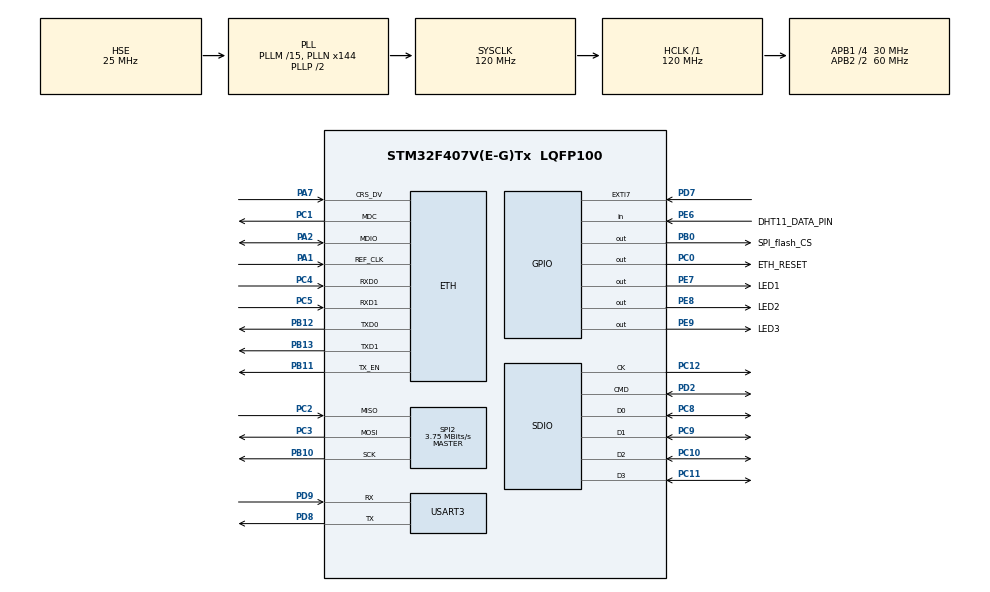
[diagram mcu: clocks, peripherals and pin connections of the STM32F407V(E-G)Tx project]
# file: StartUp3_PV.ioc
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Dma.Request0=USART3_TX
Dma.USART3_TX.0.Channel=DMA_CHANNEL_4
Dma.USART3_TX.0.Direction=DMA_MEMORY_TO_PERIPH
Dma.USART3_TX.0.FIFOMode=DMA_FIFOMODE_DISABLE
Dma.USART3_TX.0.Instance=DMA1_Stream3
Dma.USART3_TX.0.MemDataAlignment=DMA_MDATAALIGN_BYTE
Dma.USART3_TX.0.MemInc=DMA_MINC_ENABLE
Dma.USART3_TX.0.Mode=DMA_NORMAL
Dma.USART3_TX.0.PeriphDataAlignment=DMA_PDATAALIGN_BYTE
Dma.USART3_TX.0.PeriphInc=DMA_PINC_DISABLE
Dma.USART3_TX.0.Priority=DMA_PRIORITY_LOW
ETH.MACAddr=00\:80\:E1\:00\:00\:02
ETH.MediaInterface=ETH_MEDIA_INTERFACE_RMII
ETH.PHY_READ_TO=0x0004FFFF
ETH.PHY_WRITE_TO=0x0004FFFF
ETH.PhyAddress=0
FREERTOS.BinarySemaphores01=recFlag
FREERTOS.Tasks01=defaultTask,0,128,StartDefaultTask,Default
LWIP.LWIP_NETIF_LINK_CALLBACK=1
LWIP.LWIP_NETIF_LOOPBACK=0
LWIP.LWIP_NETIF_STATUS_CALLBACK=1
LWIP.LWIP_UDP=1
LWIP.MEMP_NUM_TCP_PCB=6
LWIP.MEMP_NUM_UDP_PCB=3
LWIP.TCP_TTL=63
Mcu.Family=STM32F4
Mcu.Name=STM32F407V(E-G)Tx
Mcu.Package=LQFP100
NVIC.DMA1_Stream3_IRQn=true\:5\:0\:false\:false\:true
NVIC.ETH_IRQn=true\:5\:0\:false\:false\:true
NVIC.EXTI9_5_IRQn=true\:13\:0\:true\:false\:true
NVIC.PriorityGroup=NVIC_PRIORITYGROUP_4
NVIC.SDIO_IRQn=true\:13\:0\:true\:false\:true
NVIC.SPI2_IRQn=true\:13\:0\:true\:false\:true
NVIC.TIM4_IRQn=true\:13\:0\:true\:false\:true
NVIC.TIM6_DAC_IRQn=true\:0\:0\:false\:false\:true
NVIC.TIM7_IRQn=true\:13\:0\:true\:false\:true
NVIC.TimeBase=TIM6_DAC_IRQn
NVIC.TimeBaseIP=TIM6
NVIC.USART3_IRQn=true\:13\:0\:true\:false\:true
PA1.Mode=RMII
PA1.Signal=ETH_REF_CLK
PA13.Mode=Serial-Wire
PA13.Signal=SYS_JTMS-SWDIO
PA14.Mode=Serial-Wire
PA14.Signal=SYS_JTCK-SWCLK
PA2.Mode=RMII
PA2.Signal=ETH_MDIO
PA7.Mode=RMII
PA7.Signal=ETH_CRS_DV
PB0.GPIO_Label=SPI_flash_CS
PB0.Signal=GPIO_Output
PB10.GPIO_PuPd=GPIO_PULLDOWN
PB10.GPIO_Speed=GPIO_SPEED_FREQ_HIGH
PB10.Mode=Full_Duplex_Master
PB10.Signal=SPI2_SCK
PB11.Mode=RMII
PB11.Signal=ETH_TX_EN
PB12.Mode=RMII
PB12.Signal=ETH_TXD0
PB13.Mode=RMII
PB13.Signal=ETH_TXD1
PC0.GPIO_Label=ETH_RESET
PC0.GPIO_PuPd=GPIO_PULLDOWN
PC0.Signal=GPIO_Output
PC1.Mode=RMII
PC1.Signal=ETH_MDC
PC10.Mode=SD_4_bits_Wide_bus
PC10.Signal=SDIO_D2
PC11.Mode=SD_4_bits_Wide_bus
PC11.Signal=SDIO_D3
PC12.Mode=SD_4_bits_Wide_bus
PC12.Signal=SDIO_CK
PC2.GPIO_Speed=GPIO_SPEED_FREQ_HIGH
PC2.Mode=Full_Duplex_Master
PC2.Signal=SPI2_MISO
PC3.GPIO_Speed=GPIO_SPEED_FREQ_HIGH
PC3.Mode=Full_Duplex_Master
PC3.Signal=SPI2_MOSI
PC4.Mode=RMII
PC4.Signal=ETH_RXD0
PC5.Mode=RMII
PC5.Signal=ETH_RXD1
PC8.Mode=SD_4_bits_Wide_bus
PC8.Signal=SDIO_D0
PC9.Mode=SD_4_bits_Wide_bus
PC9.Signal=SDIO_D1
PD2.Mode=SD_4_bits_Wide_bus
PD2.Signal=SDIO_CMD
PD7.Signal=GPXTI7
PD8.Mode=Asynchronous
PD8.Signal=USART3_TX
PD9.Mode=Asynchronous
PD9.Signal=USART3_RX
PE6.GPIO_Label=DHT11_DATA_PIN
PE6.GPIO_PuPd=GPIO_PULLUP
PE6.Signal=GPIO_Input
PE7.GPIO_Label=LED1
PE7.Signal=GPIO_Output
PE8.GPIO_Label=LED2
PE8.Signal=GPIO_Output
PE9.GPIO_Label=LED3
PE9.Signal=GPIO_Output
PH0-OSC_IN.Mode=HSE-External-Oscillator
PH0-OSC_IN.Signal=RCC_OSC_IN
PH1-OSC_OUT.Mode=HSE-External-Oscillator
PH1-OSC_OUT.Signal=RCC_OSC_OUT
ProjectManager.HeapSize=0x4000
ProjectManager.StackSize=0x4000
ProjectManager.TargetToolchain=MDK-ARM V5
RCC.48MHZClocksFreq_Value=48000000
RCC.AHBFreq_Value=120000000
RCC.APB1CLKDivider=RCC_HCLK_DIV4
RCC.APB1Freq_Value=30000000
RCC.APB1TimFreq_Value=60000000
RCC.APB2CLKDivider=RCC_HCLK_DIV2
RCC.APB2Freq_Value=60000000
RCC.APB2TimFreq_Value=120000000
RCC.CortexFreq_Value=120000000
RCC.HCLKFreq_Value=120000000
RCC.HSE_VALUE=25000000
RCC.HSI_VALUE=16000000
RCC.LSE_VALUE=32768
RCC.PLLM=15
RCC.PLLN=144
RCC.PLLQ=5
RCC.PLLSourceVirtual=RCC_PLLSOURCE_HSE
RCC.SYSCLKFreq_VALUE=120000000
RCC.SYSCLKSource=RCC_SYSCLKSOURCE_PLLCLK
RCC.VCOOutputFreq_Value=240000000
SDIO.BusWide=SDIO_BUS_WIDE_1B
SDIO.WideMode=SDIO_BUS_WIDE_4B
SPI2.BaudRatePrescaler=SPI_BAUDRATEPRESCALER_8
SPI2.CalculateBaudRate=3.75 MBits/s
SPI2.Mode=SPI_MODE_MASTER
TIM4.ClockDivision=TIM_CLOCKDIVISION_DIV1
TIM4.Period=0xffff
TIM4.Prescaler=59
TIM7.Period=1750
TIM7.Prescaler=59
USART3.OverSampling=UART_OVERSAMPLING_16
VP_FREERTOS_VS_ENABLE.Mode=Enabled
VP_LWIP_VS_Enabled.Mode=Enabled
VP_SYS_VS_tim6.Mode=TIM6
VP_TIM4_VS_ClockSourceINT.Mode=Internal
VP_TIM7_VS_ClockSourceINT.Mode=Enable_Timer
board=StartUp3_PV

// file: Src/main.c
/**
  ******************************************************************************
  * File Name          : main.c
  * Description        : Main program body
  ******************************************************************************
  *
  * COPYRIGHT(c) 2016 STMicroelectronics
  *
  * Redistribution and use in source and binary forms, with or without modification,
  * are permitted provided that the following conditions are met:
  *   1. Redistributions of source code must retain the above copyright notice,
  *      this list of conditions and the following disclaimer.
  *   2. Redistributions in binary form must reproduce the above copyright notice,
  *      this list of conditions and the following disclaimer in the documentation
  *      and/or other materials provided with the distribution.
  *   3. Neither the name of STMicroelectronics nor the names of its contributors
  *      may be used to endorse or promote products derived from this software
  *      without specific prior written permission.
  *
  * THIS SOFTWARE IS PROVIDED BY THE COPYRIGHT HOLDERS AND CONTRIBUTORS "AS IS"
  * AND ANY EXPRESS OR IMPLIED WARRANTIES, INCLUDING, BUT NOT LIMITED TO, THE
  * IMPLIED WARRANTIES OF MERCHANTABILITY AND FITNESS FOR A PARTICULAR PURPOSE ARE
  * DISCLAIMED. IN NO EVENT SHALL THE COPYRIGHT HOLDER OR CONTRIBUTORS BE LIABLE
  * FOR ANY DIRECT, INDIRECT, INCIDENTAL, SPECIAL, EXEMPLARY, OR CONSEQUENTIAL
  * DAMAGES (INCLUDING, BUT NOT LIMITED TO, PROCUREMENT OF SUBSTITUTE GOODS OR
  * SERVICES; LOSS OF USE, DATA, OR PROFITS; OR BUSINESS INTERRUPTION) HOWEVER
  * CAUSED AND ON ANY THEORY OF LIABILITY, WHETHER IN CONTRACT, STRICT LIABILITY,
  * OR TORT (INCLUDING NEGLIGENCE OR OTHERWISE) ARISING IN ANY WAY OUT OF THE USE
  * OF THIS SOFTWARE, EVEN IF ADVISED OF THE POSSIBILITY OF SUCH DAMAGE.
  *
  ******************************************************************************
  */
#include "stm32f4xx_hal.h"
#include "cmsis_os.h"
#include "lwip.h"

/* USER CODE BEGIN Includes */
#include "utask.h"
#include <string.h>
#include <stdlib.h>
/* USER CODE END Includes */

SD_HandleTypeDef hsd;
HAL_SD_CardInfoTypedef SDCardInfo;

SPI_HandleTypeDef hspi2;

TIM_HandleTypeDef htim4;
TIM_HandleTypeDef htim7;

UART_HandleTypeDef huart3;
DMA_HandleTypeDef hdma_usart3_tx;

osThreadId defaultTaskHandle;
osSemaphoreId recFlagHandle;

/* USER CODE BEGIN PV */
/* Private variables ---------------------------------------------------------*/

/* USER CODE END PV */

void SystemClock_Config(void);
static void MX_GPIO_Init(void);
static void MX_DMA_Init(void);
static void MX_SDIO_SD_Init(void);
static void MX_SPI2_Init(void);
static void MX_TIM7_Init(void);
static void MX_USART3_UART_Init(void);
static void MX_TIM4_Init(void);
void StartDefaultTask(void const * argument);

/* USER CODE BEGIN PFP */
/* Private function prototypes -----------------------------------------------*/

/* USER CODE END PFP */

int main(void)
{

  /* MCU Configuration----------------------------------------------------------*/

  /* Reset of all peripherals, Initializes the Flash interface and the Systick. */
  HAL_Init();

  /* Configure the system clock */
  SystemClock_Config();

  /* Initialize all configured peripherals */
  MX_GPIO_Init();
  MX_DMA_Init();
  MX_SDIO_SD_Init();
  MX_SPI2_Init();
  MX_TIM7_Init();
  MX_USART3_UART_Init();
  MX_TIM4_Init();

  /* USER CODE BEGIN 2 */
	HAL_CalTick();
  /* USER CODE END 2 */

  /* Create the semaphores(s) */
  /* definition and creation of recFlag */
  osSemaphoreDef(recFlag);
  recFlagHandle = osSemaphoreCreate(osSemaphore(recFlag), 1);

  /* Create the thread(s) */
  /* definition and creation of defaultTask */
  osThreadDef(defaultTask, StartDefaultTask, osPriorityNormal, 0, 128);
  defaultTaskHandle = osThreadCreate(osThread(defaultTask), NULL);

  /* USER CODE BEGIN RTOS_THREADS */
  /* add threads, ... */
  xTaskCreate(TCPClt, "TCP Client demo", 512, NULL, 3, NULL);
  xTaskCreate(Pub_SENSOR, "Pub Tem Hum", 128, NULL, 3, NULL);
	xTaskCreate(StartPacketsProcess, "UART RECEIVE", 128, NULL, 3, NULL);
  /* USER CODE END RTOS_THREADS */

  /* USER CODE BEGIN RTOS_QUEUES */
  /* add queues, ... */
  xPubQueue = xQueueCreate(6, 4);
  /* USER CODE END RTOS_QUEUES */

  /* Start scheduler */
  osKernelStart();

  /* We should never get here as control is now taken by the scheduler */

  /* Infinite loop */
  while (1)
  {

  }

}

/** System Clock Configuration
*/
void SystemClock_Config(void)
{

  RCC_OscInitTypeDef RCC_OscInitStruct;
  RCC_ClkInitTypeDef RCC_ClkInitStruct;

  __HAL_RCC_PWR_CLK_ENABLE();

  __HAL_PWR_VOLTAGESCALING_CONFIG(PWR_REGULATOR_VOLTAGE_SCALE1);

  RCC_OscInitStruct.OscillatorType = RCC_OSCILLATORTYPE_HSE;
  RCC_OscInitStruct.HSEState = RCC_HSE_ON;
  RCC_OscInitStruct.PLL.PLLState = RCC_PLL_ON;
  RCC_OscInitStruct.PLL.PLLSource = RCC_PLLSOURCE_HSE;
  RCC_OscInitStruct.PLL.PLLM = 15;
  RCC_OscInitStruct.PLL.PLLN = 144;
  RCC_OscInitStruct.PLL.PLLP = RCC_PLLP_DIV2;
  RCC_OscInitStruct.PLL.PLLQ = 5;
  HAL_RCC_OscConfig(&RCC_OscInitStruct);

  RCC_ClkInitStruct.ClockType = RCC_CLOCKTYPE_HCLK|RCC_CLOCKTYPE_SYSCLK
                              |RCC_CLOCKTYPE_PCLK1|RCC_CLOCKTYPE_PCLK2;
  RCC_ClkInitStruct.SYSCLKSource = RCC_SYSCLKSOURCE_PLLCLK;
  RCC_ClkInitStruct.AHBCLKDivider = RCC_SYSCLK_DIV1;
  RCC_ClkInitStruct.APB1CLKDivider = RCC_HCLK_DIV4;
  RCC_ClkInitStruct.APB2CLKDivider = RCC_HCLK_DIV2;
  HAL_RCC_ClockConfig(&RCC_ClkInitStruct, FLASH_LATENCY_3);

  HAL_SYSTICK_Config(HAL_RCC_GetHCLKFreq()/1000);

  HAL_SYSTICK_CLKSourceConfig(SYSTICK_CLKSOURCE_HCLK);

  /* SysTick_IRQn interrupt configuration */
  HAL_NVIC_SetPriority(SysTick_IRQn, 15, 0);
}

/* SDIO init function */
void MX_SDIO_SD_Init(void)
{

  hsd.Instance = SDIO;
  hsd.Init.ClockEdge = SDIO_CLOCK_EDGE_RISING;
  hsd.Init.ClockBypass = SDIO_CLOCK_BYPASS_DISABLE;
  hsd.Init.ClockPowerSave = SDIO_CLOCK_POWER_SAVE_DISABLE;
  hsd.Init.BusWide = SDIO_BUS_WIDE_1B;
  hsd.Init.HardwareFlowControl = SDIO_HARDWARE_FLOW_CONTROL_DISABLE;
  hsd.Init.ClockDiv = 0;
  HAL_SD_Init(&hsd, &SDCardInfo);

  HAL_SD_WideBusOperation_Config(&hsd, SDIO_BUS_WIDE_4B);

}

/* SPI2 init function */
void MX_SPI2_Init(void)
{

  hspi2.Instance = SPI2;
  hspi2.Init.Mode = SPI_MODE_MASTER;
  hspi2.Init.Direction = SPI_DIRECTION_2LINES;
  hspi2.Init.DataSize = SPI_DATASIZE_8BIT;
  hspi2.Init.CLKPolarity = SPI_POLARITY_LOW;
  hspi2.Init.CLKPhase = SPI_PHASE_1EDGE;
  hspi2.Init.NSS = SPI_NSS_SOFT;
  hspi2.Init.BaudRatePrescaler = SPI_BAUDRATEPRESCALER_8;
  hspi2.Init.FirstBit = SPI_FIRSTBIT_MSB;
  hspi2.Init.TIMode = SPI_TIMODE_DISABLE;
  hspi2.Init.CRCCalculation = SPI_CRCCALCULATION_DISABLE;
  hspi2.Init.CRCPolynomial = 10;
  HAL_SPI_Init(&hspi2);

}

/* TIM4 init function */
void MX_TIM4_Init(void)
{

  TIM_ClockConfigTypeDef sClockSourceConfig;
  TIM_MasterConfigTypeDef sMasterConfig;

  htim4.Instance = TIM4;
  htim4.Init.Prescaler = 59;
  htim4.Init.CounterMode = TIM_COUNTERMODE_UP;
  htim4.Init.Period = 0xffff;
  htim4.Init.ClockDivision = TIM_CLOCKDIVISION_DIV1;
  HAL_TIM_Base_Init(&htim4);

  sClockSourceConfig.ClockSource = TIM_CLOCKSOURCE_INTERNAL;
  HAL_TIM_ConfigClockSource(&htim4, &sClockSourceConfig);

  sMasterConfig.MasterOutputTrigger = TIM_TRGO_RESET;
  sMasterConfig.MasterSlaveMode = TIM_MASTERSLAVEMODE_DISABLE;
  HAL_TIMEx_MasterConfigSynchronization(&htim4, &sMasterConfig);

}

/* TIM7 init function */
void MX_TIM7_Init(void)
{

  TIM_MasterConfigTypeDef sMasterConfig;

  htim7.Instance = TIM7;
  htim7.Init.Prescaler = 59;
  htim7.Init.CounterMode = TIM_COUNTERMODE_UP;
  htim7.Init.Period = 1750;
  HAL_TIM_Base_Init(&htim7);

  sMasterConfig.MasterOutputTrigger = TIM_TRGO_RESET;
  sMasterConfig.MasterSlaveMode = TIM_MASTERSLAVEMODE_DISABLE;
  HAL_TIMEx_MasterConfigSynchronization(&htim7, &sMasterConfig);

}

/* USART3 init function */
void MX_USART3_UART_Init(void)
{

  huart3.Instance = USART3;
  huart3.Init.BaudRate = 115200;
  huart3.Init.WordLength = UART_WORDLENGTH_8B;
  huart3.Init.StopBits = UART_STOPBITS_1;
  huart3.Init.Parity = UART_PARITY_NONE;
  huart3.Init.Mode = UART_MODE_TX_RX;
  huart3.Init.HwFlowCtl = UART_HWCONTROL_NONE;
  huart3.Init.OverSampling = UART_OVERSAMPLING_16;
  HAL_UART_Init(&huart3);

}

void MX_DMA_Init(void)
{
  /* DMA controller clock enable */
  __HAL_RCC_DMA1_CLK_ENABLE();

  /* DMA interrupt init */
  /* DMA1_Stream3_IRQn interrupt configuration */
  HAL_NVIC_SetPriority(DMA1_Stream3_IRQn, 5, 0);
  HAL_NVIC_EnableIRQ(DMA1_Stream3_IRQn);

}

/** Configure pins as
        * Analog
        * Input
        * Output
        * EVENT_OUT
        * EXTI
*/
void MX_GPIO_Init(void)
{

  GPIO_InitTypeDef GPIO_InitStruct;

  /* GPIO Ports Clock Enable */
  __HAL_RCC_GPIOE_CLK_ENABLE();
  __HAL_RCC_GPIOH_CLK_ENABLE();
  __HAL_RCC_GPIOC_CLK_ENABLE();
  __HAL_RCC_GPIOA_CLK_ENABLE();
  __HAL_RCC_GPIOB_CLK_ENABLE();
  __HAL_RCC_GPIOD_CLK_ENABLE();

  /*Configure GPIO pin : DHT11_DATA_PIN_Pin */
  GPIO_InitStruct.Pin = DHT11_DATA_PIN_Pin;
  GPIO_InitStruct.Mode = GPIO_MODE_INPUT;
  GPIO_InitStruct.Pull = GPIO_PULLUP;
  HAL_GPIO_Init(DHT11_DATA_PIN_GPIO_Port, &GPIO_InitStruct);

  /*Configure GPIO pin : ETH_RESET_Pin */
  GPIO_InitStruct.Pin = ETH_RESET_Pin;
  GPIO_InitStruct.Mode = GPIO_MODE_OUTPUT_PP;
  GPIO_InitStruct.Pull = GPIO_PULLDOWN;
  GPIO_InitStruct.Speed = GPIO_SPEED_FREQ_LOW;
  HAL_GPIO_Init(ETH_RESET_GPIO_Port, &GPIO_InitStruct);

  /*Configure GPIO pin : SPI_flash_CS_Pin */
  GPIO_InitStruct.Pin = SPI_flash_CS_Pin;
  GPIO_InitStruct.Mode = GPIO_MODE_OUTPUT_PP;
  GPIO_InitStruct.Pull = GPIO_NOPULL;
  GPIO_InitStruct.Speed = GPIO_SPEED_FREQ_LOW;
  HAL_GPIO_Init(SPI_flash_CS_GPIO_Port, &GPIO_InitStruct);

  /*Configure GPIO pins : LED1_Pin LED2_Pin LED3_Pin */
  GPIO_InitStruct.Pin = LED1_Pin|LED2_Pin|LED3_Pin;
  GPIO_InitStruct.Mode = GPIO_MODE_OUTPUT_PP;
  GPIO_InitStruct.Pull = GPIO_NOPULL;
  GPIO_InitStruct.Speed = GPIO_SPEED_FREQ_LOW;
  HAL_GPIO_Init(GPIOE, &GPIO_InitStruct);

  /*Configure GPIO pin : PD7 */
  GPIO_InitStruct.Pin = GPIO_PIN_7;
  GPIO_InitStruct.Mode = GPIO_MODE_IT_RISING;
  GPIO_InitStruct.Pull = GPIO_NOPULL;
  HAL_GPIO_Init(GPIOD, &GPIO_InitStruct);

  /*Configure GPIO pin Output Level */
  HAL_GPIO_WritePin(ETH_RESET_GPIO_Port, ETH_RESET_Pin, GPIO_PIN_RESET);

  /*Configure GPIO pin Output Level */
  HAL_GPIO_WritePin(SPI_flash_CS_GPIO_Port, SPI_flash_CS_Pin, GPIO_PIN_RESET);

  /*Configure GPIO pin Output Level */
  HAL_GPIO_WritePin(GPIOE, LED1_Pin|LED2_Pin|LED3_Pin, GPIO_PIN_RESET);

  /* EXTI interrupt init*/
  HAL_NVIC_SetPriority(EXTI9_5_IRQn, 13, 0);
  HAL_NVIC_EnableIRQ(EXTI9_5_IRQn);

}

/* StartDefaultTask function */
void StartDefaultTask(void const * argument)
{
  /* init code for LWIP */
  MX_LWIP_Init();

  /* USER CODE BEGIN 5 */
  __HAL_UART_ENABLE_IT(&huart3, UART_IT_RXNE);
  osDelay(1);
  /* Infinite loop */
  for(;;)
  {
	  LED_Toggle(1);
	  osDelay(1000);
  }
  /* USER CODE END 5 */
}

/************************ (C) COPYRIGHT STMicroelectronics *****END OF FILE****/
